AUTOSAR XML (schema 4-3-0)
standard types defined: boolean, uint16, uint8
package /Communication/Frames
  can frame DebugMsg1: frame-length=8
    pdu to frame mapping DebugMsg1: packing-byte-order=little-endian, pdu=DebugMsg1, start-position=0
package /Communication/NetworkManagement
  nm config NmConfig: can-nm-cluster-coupling=coupled-cluster=CAN00_CAN
    can nm cluster CAN00_CAN: communication-cluster=Comfort, nm-channel-id=0, nm-msg-cycle-time=2, nm-network-timeout=1, nm-repeat-message-time=0.4, nm-user-data-length=5, nm-wait-bus-sleep-time=0.75
      4 x can nm node, all with nm-car-wake-up-filter-enabled=false, nm-car-wake-up-rx-enabled=false, nm-msg-cycle-offset=0.01, nm-msg-reduced-time=0.05, nm-range-config={lower-can-id=1280, upper-can-id=1407}:
        Console: controller=Console/CT_CAN00, nm-if-ecu=Console_CAN, nm-node-id=-230, tx-nm-pdu=NM_Console
        DOOR_le: controller=DOOR_le/CT_CAN00, nm-if-ecu=DOOR_le_CAN, nm-node-id=-229, rx-nm-pdu=[NM_Console, NM_DOORright, NM_Gateway], tx-nm-pdu=NM_DOORleft
        DOOR_ri: controller=DOOR_ri/CT_CAN00, nm-if-ecu=DOOR_ri_CAN, nm-node-id=-228, rx-nm-pdu=[NM_Console, NM_DOORleft, NM_Gateway], tx-nm-pdu=NM_DOORright
        Gateway: controller=Gateway/CT_CAN00, nm-if-ecu=Gateway_CAN, nm-node-id=-227, rx-nm-pdu=[NM_Console, NM_DOORleft, NM_DOORright], tx-nm-pdu=NM_Gateway
    nm-if-ecus:
      4 x nm ecu, all with nm-node-id-enabled=true, nm-passive-mode-enabled=false, nm-user-data-enabled=true:
        Console_CAN: ecu-instance=Console
        DOOR_le_CAN: ecu-instance=DOOR_le
        DOOR_ri_CAN: ecu-instance=DOOR_ri
        Gateway_CAN: ecu-instance=Gateway
package /Communication/PDUs
  pdu Auth_PDU_1: length=8, transmission-mode-true-timing=cyclic-timing={time-offset=0, time-period=0.1}
    signal AuthPDU1_Signal1: start 0, 32 bit, little-endian, init-value=0, base-type=uint8
  pdu Auth_PDU_2: length=8, transmission-mode-true-timing=cyclic-timing={time-offset=0, time-period=0.1}
    signal AuthPDU2_Signal1: start 0, 32 bit, little-endian, init-value=0, base-type=uint8
  pdu DebugMsg1: length=8, minimum-delay=0, unused-bit-pattern=0
    signal DebugMsg1: start 0, 64 bit, opaque, init-value=8 x 0, base-type=uint8_8_iso_8859_1, compu {phys=raw for raw 0..1.84467440737096e+19}, transfer-property=PENDING, to Gateway
  18 x i signal i pdu group:
    Console_Rx: communication-direction=IN, i-signal-i-pdus=[Gateway_1, TP_Dashboard]
    Console_Tx: communication-direction=OUT, i-signal-i-pdus=[Console_1, Console_2, TP_Console]
    DOOR_le_Rx: communication-direction=IN, i-signal-i-pdus=Console_1
    DOOR_le_Tx: communication-direction=OUT, i-signal-i-pdus=DOOR_l
    DOOR_ri_Rx: communication-direction=IN, i-signal-i-pdus=Console_1
    DOOR_ri_Tx: communication-direction=OUT, i-signal-i-pdus=DOOR_r
    Dashboard_Rx: communication-direction=IN, i-signal-i-pdus=[Gateway_1, Gateway_2, TP_Console]
    Dashboard_Tx: communication-direction=OUT, i-signal-i-pdus=TP_Dashboard
    Gateway_Rx: communication-direction=IN, i-signal-i-pdus=DebugMsg1
    Gateway_Tx: communication-direction=OUT, i-signal-i-pdus=[Gateway_1, Gateway_2]
    PduGroup_203ad921c8f5452f95344f69f3b2c7c1_Tx: communication-direction=OUT
    PduGroup_2c8cbd7ae1c24b01b320fa2d7fbdce5a_Rx: communication-direction=IN
    PduGroup_42a827080d59494ea335cf739e6b9c29_Rx: communication-direction=IN
    PduGroup_4639c418dbec4715b125f02d3bcf57bf_Tx: communication-direction=OUT
    PduGroup_49c142dee3aa42039fa139536eb9d00c_Tx: communication-direction=OUT
    PduGroup_4a711ec297f94c7e811063aed12ba3a3_Rx: communication-direction=IN
    PduGroup_752b803f1d4a4f3696c5d022bdbd7b0a_Tx: communication-direction=OUT
    PduGroup_d31b664e874842edb94667f4a31f5902_Rx: communication-direction=IN
  pdu Multimedia_Contained1: length=20, contained-i-pdu-props={collection-semantics=LAST-IS-BEST, header-id-short-header=1, trigger=NEVER}, transmission-mode-true-timing={cyclic-timing=time-period=0.2, event-controlled-timing=number-of-repetitions=0}
    signal Multimedia_Contained1_Signal: start 0, 8 bit, little-endian, data-type-policy=OVERRIDE, base-type=uint16, to Dashboard
  pdu Multimedia_Contained2: length=20, contained-i-pdu-props={collection-semantics=LAST-IS-BEST, header-id-short-header=2, trigger=ALWAYS}, transmission-mode-condition{data-filter=data-filter-type=ALWAYS, i-signal-in-i-pdu=SignalPduMapping_683b95378b008a29}, transmission-mode-true-timing={cyclic-timing=time-period=0.1, event-controlled-timing=number-of-repetitions=0}
    signal Multimedia_Contained2_Signal: start 0, 8 bit, little-endian, data-type-policy=OVERRIDE, base-type=uint16, transfer-property=PENDING, to Dashboard
  pdu Multimedia_Contained3: length=30, contained-i-pdu-props={collection-semantics=LAST-IS-BEST, header-id-short-header=3, trigger=NEVER}, transmission-mode-true-timing=event-controlled-timing=number-of-repetitions=0
    signal Multimedia_Contained3_Signal: start 0, 64 bit, little-endian, data-type-policy=OVERRIDE, init-value=X64bit:23456789, base-type=uint16, to Dashboard
  pdu Multimedia_Contained4: length=30, contained-i-pdu-props={collection-semantics=LAST-IS-BEST, header-id-short-header=4, trigger=ALWAYS}, transmission-mode-true-timing=event-controlled-timing=number-of-repetitions=0
    signal Multimedia_Contained4_Signal: start 0, 32 bit, little-endian, data-type-policy=OVERRIDE, init-value=X32bit:012345, base-type=uint16, to Dashboard
package /Communication/Security
  secure communication props set SecurityConfigurarion
    secure communication authentication props AuthenticationProperties: auth-info-tx-length=24
    secure communication freshness props FreshnessProperties: freshness-value-length=8, freshness-value-tx-length=8
package /Communication/TransportProtocol
  can tp config CAN00_CAN: communication-cluster=Comfort
    can tp channel TPCH: channel-id=0, channel-mode=FULL-DUPLEX-MODE
package /DataTypes/ApplicationDataTypes
  app type Boolean: category=BOOLEAN
  app type String: category=STRING
package /DataTypes/BaseTypes
  base type uint8_6_iso_8859_1: category=FIXED_LENGTH, base-type-size=48, base-type-encoding=ISO-8859-1, mem-alignment=0
  base type uint8_8_iso_8859_1: category=FIXED_LENGTH, base-type-size=64, base-type-encoding=ISO-8859-1, mem-alignment=0
package /DataTypes/Units
  5 x unit:
    U_V: display-name=V
    U_degC: display-name=degC
    U_l: display-name=l
    U_mph: display-name=mph
    U_rpm: display-name=rpm
package /System
  system System
package /Topology/Clusters
  can cluster Comfort: baudrate=500000, protocol-name=CAN, can-fd-baudrate=4000000  # democomfort | CAN communication matrix for body electronics*******************************************************implemented: turn lights, warning lights, windows
    can physical channel CHNL: comm-connectors=[CN_CAN00_Console, CN_CAN00_DOOR_le, CN_CAN00_DOOR_ri, CN_CAN00_Dashboard, CN_CAN00_GW]
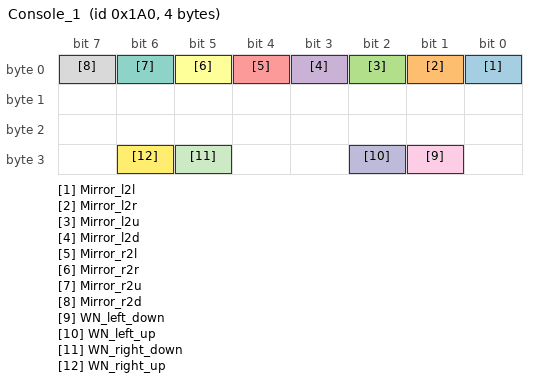
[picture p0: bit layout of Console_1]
      frame Console_1: id 0x1A0, from Console, to DOOR_le DOOR_ri, frame-length=4, can-addressing-mode=STANDARD, can-frame-tx-behavior=CAN-20
        pdu Console_1: length=4, minimum-delay=0.001, transmission-mode-false-timing=cyclic-timing={time-offset=0, time-period=0.02}, transmission-mode-true-timing=cyclic-timing={time-offset=0, time-period=0.02}, unused-bit-pattern=0
          signal Mirror_l2l: start 0, 1 bit, little-endian, init-value=0, base-type=boolean, compu {phys=raw for raw 0..1}, transfer-property=PENDING
          signal Mirror_l2r: start 1, 1 bit, little-endian, init-value=0, base-type=boolean, compu {phys=raw for raw 0..1}, transfer-property=PENDING
          signal Mirror_l2u: start 2, 1 bit, little-endian, init-value=0, base-type=boolean, compu {phys=raw for raw 0..1}, transfer-property=PENDING
          signal Mirror_l2d: start 3, 1 bit, little-endian, init-value=0, base-type=boolean, compu {phys=raw for raw 0..1}, transfer-property=PENDING
          signal Mirror_r2l: start 4, 1 bit, little-endian, init-value=0, base-type=boolean, compu {phys=raw for raw 0..1}, transfer-property=PENDING
          signal Mirror_r2r: start 5, 1 bit, little-endian, init-value=0, base-type=boolean, compu {phys=raw for raw 0..1}, transfer-property=PENDING
          signal Mirror_r2u: start 6, 1 bit, little-endian, init-value=0, base-type=boolean, compu {phys=raw for raw 0..1}, transfer-property=PENDING
          signal Mirror_r2d: start 7, 1 bit, little-endian, init-value=0, base-type=boolean, compu {phys=raw for raw 0..1}, transfer-property=PENDING
          signal WN_left_down: start 25, 1 bit, little-endian, init-value=0, base-type=boolean, compu {phys=raw for raw 0..1}, transfer-property=PENDING, to DOOR_le
          signal WN_left_up: start 26, 1 bit, little-endian, init-value=0, base-type=boolean, compu {phys=raw for raw 0..1}, transfer-property=PENDING, to DOOR_le
          signal WN_right_down: start 29, 1 bit, little-endian, init-value=0, base-type=boolean, compu {phys=raw for raw 0..1}, transfer-property=PENDING, to DOOR_ri
          signal WN_right_up: start 30, 1 bit, little-endian, init-value=0, base-type=boolean, compu {phys=raw for raw 0..1}, transfer-property=PENDING, to DOOR_ri
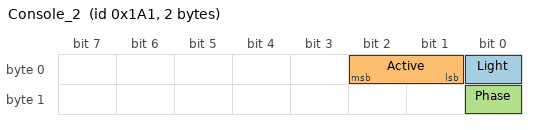
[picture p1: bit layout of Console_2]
      frame Console_2: id 0x1A1, from Console, frame-length=2, can-addressing-mode=STANDARD, can-frame-tx-behavior=CAN-20
        pdu Console_2: length=2, minimum-delay=0.001, transmission-mode-condition{data-filter={data-filter-type=MASKED-NEW-DIFFERS-X, mask=1, x=0}, i-signal-in-i-pdu=Light}, transmission-mode-false-timing=cyclic-timing=time-period=0.5, transmission-mode-true-timing=cyclic-timing=time-period=0.1, unused-bit-pattern=0
          signal Light: start 0, 1 bit, little-endian, init-value=0, base-type=boolean, compu {phys=raw for raw 0..1, 0=Light_Off, 1=Light_On}, transfer-property=PENDING
          signal Active: start 1, 2 bit, little-endian, init-value=0, base-type=uint8, compu {0=None, 1=Turn_right, 2=Turn_left, 3=Warning}, transfer-property=PENDING
          signal Phase: start 8, 1 bit, little-endian, init-value=0, base-type=boolean, compu {phys=raw for raw 0..1}, transfer-property=PENDING
      frame DOOR_l: id 0x1F0, from DOOR_le, frame-length=1, can-addressing-mode=STANDARD, can-frame-tx-behavior=CAN-20
        pdu DOOR_l: length=1, minimum-delay=0.001, transmission-mode-false-timing=cyclic-timing=time-period=0.03, transmission-mode-true-timing=cyclic-timing=time-period=0.03, unused-bit-pattern=0
          signal WN_Position: start 0, 8 bit, little-endian, init-value=0, base-type=uint8, compu {phys=raw*0.0625 for raw 0..255}, transfer-property=PENDING
      frame DOOR_r: id 0x1F1, from DOOR_ri, frame-length=1, can-addressing-mode=STANDARD, can-frame-tx-behavior=CAN-20
        pdu DOOR_r: length=1, minimum-delay=0.001, transmission-mode-false-timing=cyclic-timing=time-period=0.03, transmission-mode-true-timing=cyclic-timing=time-period=0.03, unused-bit-pattern=0
          signal WN_Position_Passenger: start 0, 8 bit, little-endian, init-value=0, base-type=uint8, compu {phys=raw*0.0625 for raw 0..255}, transfer-property=PENDING
      frame Diag_Request: id 0x700, frame-length=8, can-addressing-mode=STANDARD
        user defined pdu Diag_Request: length=8
      frame Diag_Response: id 0x600, frame-length=8, can-addressing-mode=STANDARD
        user defined pdu Diag_Response: length=8
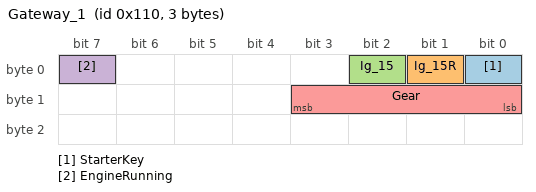
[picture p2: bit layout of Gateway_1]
      frame Gateway_1: id 0x110, from Gateway, to Console Dashboard, frame-length=3, can-addressing-mode=STANDARD, can-frame-tx-behavior=CAN-20
        pdu Gateway_1: length=3, minimum-delay=0.001, transmission-mode-false-timing=cyclic-timing=time-period=0.1, transmission-mode-true-timing=cyclic-timing=time-period=0.1, unused-bit-pattern=0
          signal StarterKey: start 0, 1 bit, little-endian, init-value=0, base-type=boolean, compu {phys=raw for raw 0..1}, transfer-property=PENDING, to Dashboard
          signal Ig_15R: start 1, 1 bit, little-endian, init-value=0, base-type=boolean, compu {phys=raw for raw 0..1}, transfer-property=PENDING, to Dashboard
          signal Ig_15: start 2, 1 bit, little-endian, init-value=0, base-type=boolean, compu {phys=raw for raw 0..1}, transfer-property=PENDING, to Console Dashboard
          signal EngineRunning: start 7, 1 bit, little-endian, init-value=0, base-type=boolean, compu {phys=raw for raw 0..1}, transfer-property=PENDING
          signal Gear: start 8, 4 bit, little-endian, init-value=0, base-type=uint8, compu {phys=raw for raw 0..15}, transfer-property=PENDING, to Dashboard
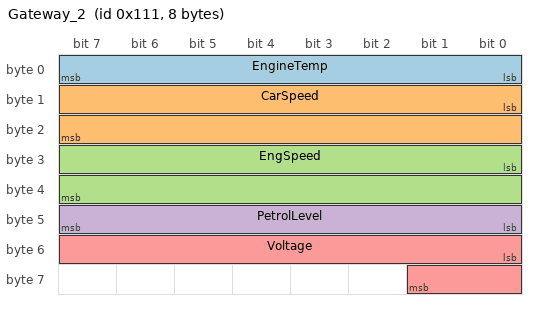
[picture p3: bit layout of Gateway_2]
      frame Gateway_2: id 0x111, from Gateway, to Dashboard, frame-length=8, can-addressing-mode=STANDARD, can-frame-tx-behavior=CAN-20
        pdu Gateway_2: length=8, minimum-delay=0.001, transmission-mode-false-timing={cyclic-timing=time-period=0.1, event-controlled-timing={number-of-repetitions=0, repetition-period=0}}, transmission-mode-true-timing={cyclic-timing=time-period=0.1, event-controlled-timing={number-of-repetitions=0, repetition-period=0}}, unused-bit-pattern=0
          transmission-mode-conditions:
            {data-filter={data-filter-type=MASKED-NEW-DIFFERS-MASKED-OLD, mask=255}, i-signal-in-i-pdu=EngineTemp}
            {data-filter={data-filter-type=MASKED-NEW-DIFFERS-MASKED-OLD, mask=255}, i-signal-in-i-pdu=PetrolLevel}
            {data-filter={data-filter-type=MASKED-NEW-DIFFERS-MASKED-OLD, mask=1023}, i-signal-in-i-pdu=Voltage}
            {data-filter={data-filter-type=MASKED-NEW-DIFFERS-MASKED-OLD, mask=65535}, i-signal-in-i-pdu=CarSpeed}
            {data-filter={data-filter-type=MASKED-NEW-DIFFERS-MASKED-OLD, mask=65535}, i-signal-in-i-pdu=EngSpeed}
          signal EngineTemp: start 0, 8 bit, little-endian, init-value=0, base-type=uint8, compu {phys=raw for raw 0..255; unit degC}, transfer-property=TRIGGERED, to Dashboard
          signal CarSpeed: start 8, 16 bit, little-endian, init-value=0, base-type=uint16, compu {phys=raw*0.5 for raw 0..65535; unit mph}, transfer-property=TRIGGERED, to Dashboard
          signal EngSpeed: start 24, 16 bit, little-endian, init-value=0, base-type=uint16, compu {phys=raw for raw 0..65535; unit rpm}, transfer-property=TRIGGERED, to Dashboard
          signal PetrolLevel: start 40, 8 bit, little-endian, init-value=0, base-type=uint8, compu {phys=raw for raw 0..255; unit l}, transfer-property=TRIGGERED, to Dashboard
          signal Voltage: start 48, 10 bit, little-endian, init-value=0, base-type=uint16, compu {phys=raw*0.1 for raw 0..1023; unit V}, transfer-property=TRIGGERED
      frame Mirror_Frame_1: id 0x7, from Dashboard, to Console, frame-length=16, can-addressing-mode=STANDARD, can-frame-tx-behavior=CAN-20
        pdu Mirror_Auth_PDU_1: length=16, transmission-mode-true-timing=cyclic-timing=time-period=0.1
          signal Mirror_Auth_PDU_1_NewSignal: start 0, 8 bit, little-endian, system signal Mirror_Auth_NewSignal_1, init-value=0, base-type=uint16, to Console
      frame Mirror_Frame_2: id 0x8, from Dashboard, to Console, frame-length=16, can-addressing-mode=STANDARD, can-frame-tx-behavior=CAN-20
        pdu Mirror_Auth_PDU_2: length=16, transmission-mode-true-timing=cyclic-timing=time-period=0.1
          signal Mirror_Auth_PDU_2_NewSignal: start 0, 8 bit, opaque, system signal Mirror_Auth_NewSignal_2, init-value=0, base-type=uint16, to Console
      frame NM_Console: id 0x41A, from Console, to DOOR_le DOOR_ri Dashboard Gateway, frame-length=4, can-addressing-mode=STANDARD, can-frame-tx-behavior=CAN-20
        nm pdu NM_Console: length=4, unused-bit-pattern=0
      frame NM_DOORleft: id 0x41B, from DOOR_le, to Console DOOR_ri Dashboard Gateway, frame-length=4, can-addressing-mode=STANDARD, can-frame-tx-behavior=CAN-20
        nm pdu NM_DOORleft: length=4, unused-bit-pattern=0
      frame NM_DOORright: id 0x41C, from DOOR_ri, to Console DOOR_le Dashboard Gateway, frame-length=4, can-addressing-mode=STANDARD, can-frame-tx-behavior=CAN-20
        nm pdu NM_DOORright: length=4, unused-bit-pattern=0
      frame NM_Gateway: id 0x41D, from Gateway, to Console DOOR_le DOOR_ri Dashboard, frame-length=4, can-addressing-mode=STANDARD, can-frame-tx-behavior=CAN-20
        nm pdu NM_Gateway: length=4, unused-bit-pattern=0
      frame ResetCounterSyncMessage: id 0x6, from Console, to Dashboard, frame-length=8, can-addressing-mode=STANDARD, can-frame-tx-behavior=CAN-20
        pdu ResetCounterSyncMessagePDU: length=3
          signal ResetCounterValueSignal: start 0, 24 bit, little-endian, data-type-policy=OVERRIDE
      frame ResetCounterSyncMessage_Sec: id 0x4, from Console, to Dashboard, frame-length=8, can-addressing-mode=STANDARD, can-frame-tx-behavior=CAN-FD
        secured i pdu ResetCounterSyncMessage_Sec: length=8, authentication-props=AuthenticationProperties, freshness-props=FreshnessProperties, payload=PT_ResetCounterSyncMessagePDU, secure-communication-props={auth-info-tx-length=24, data-id=22, freshness-value-id=2, freshness-value-tx-length=8, secondary-freshness-value-id=0}
        carries pdu ResetCounterValue: packing-byte-order=little-endian, start-position=64
        pdu ResetCounterValue: length=3
          signal ResetCounterValue: start 0, 24 bit, little-endian, data-type-policy=OVERRIDE
      frame Secured_Frame_1: id 0xC9, from Console, to Dashboard, frame-length=16, can-addressing-mode=STANDARD, can-frame-rx-behavior=CAN-FD, can-frame-tx-behavior=CAN-FD
        secured i pdu Secured_PDU_1: length=12, authentication-props=AuthenticationProperties, freshness-props=FreshnessProperties, payload=PT_AuthPDU1, secure-communication-props={auth-info-tx-length=24, data-id=33, freshness-value-tx-length=8}
      frame Secured_Frame_2: id 0xCA, from Console, to Dashboard, frame-length=16, can-addressing-mode=STANDARD, can-frame-rx-behavior=CAN-FD, can-frame-tx-behavior=CAN-FD
        secured i pdu Secured_PDU_2: length=12, authentication-props=AuthenticationProperties, freshness-props=FreshnessProperties, payload=PT_AuthPDU2, secure-communication-props={auth-info-tx-length=24, data-id=34, freshness-value-tx-length=8}
      frame TP_Console: id 0x604, from Console, to Dashboard, frame-length=6, can-addressing-mode=STANDARD, can-frame-tx-behavior=CAN-20
        pdu TP_Console: length=6, minimum-delay=0, unused-bit-pattern=0
          signal TP_Console: start 0, 48 bit, opaque, init-value=6 x 0, base-type=uint8_6_iso_8859_1, compu {phys=raw for raw 0..281474976710655}, transfer-property=PENDING, to Dashboard
      frame TP_Dashboard: id 0x605, from Dashboard, to Console, frame-length=6, can-addressing-mode=STANDARD, can-frame-tx-behavior=CAN-20
        pdu TP_Dashboard: length=6, minimum-delay=0, unused-bit-pattern=0
          signal TP_Dashboard: start 0, 48 bit, opaque, init-value=6 x 0, base-type=uint8_6_iso_8859_1, compu {phys=raw for raw 0..281474976710655}, transfer-property=PENDING, to Console
      frame TripCounterSyncMessage: id 0x5, from Console, to Dashboard, frame-length=8, can-addressing-mode=STANDARD, can-frame-tx-behavior=CAN-FD
        pdu TripCounterSyncMessagePDU: length=3
          signal TripCounterValueSignal: start 0, 24 bit, little-endian, data-type-policy=OVERRIDE
      frame TripCounterSyncMessage_Sec: id 0x3, from Console, to Dashboard, frame-length=8, can-addressing-mode=STANDARD, can-frame-tx-behavior=CAN-FD
        secured i pdu TripCounterSyncMessage_Sec: length=8, authentication-props=AuthenticationProperties, freshness-props=FreshnessProperties, payload=PT_TripCounterSyncMessagePDU, secure-communication-props={auth-info-tx-length=24, data-id=11, freshness-value-id=1, freshness-value-tx-length=8, secondary-freshness-value-id=0}
        carries pdu TripCounterValue: packing-byte-order=little-endian, start-position=64
        pdu TripCounterValue: length=3
          signal TripCounterValue: start 0, 24 bit, little-endian, data-type-policy=OVERRIDE
      frame Mulitmedia_Frame: id 0xC8, from Console, to Dashboard, frame-length=64, can-addressing-mode=EXTENDED
        container i pdu Multimedia: length=64, contained-pdu-triggering=[PT_Multimedia_Contained1, PT_Multimedia_Contained2, PT_Multimedia_Contained3, PT_Multimedia_Contained4], container-timeout=0.2, container-trigger=DEFAULT-TRIGGER, header-type=SHORT-HEADER, rx-accept-contained-i-pdu=ACCEPT-CONFIGURED, threshold-size=60
      frame WiperSystem: id 0x1, from Dashboard, frame-length=8, can-addressing-mode=STANDARD, can-frame-tx-behavior=CAN-20
        pdu WiperPosition: length=4, minimum-delay=0.001, transmission-mode-true-timing=cyclic-timing=time-period=0.03
          signal WiperPosition: start 0, 4 bit, little-endian, system signal WiperPosition_3b8b5377bfae9a8b, data-type-policy=OVERRIDE, base-type=uint8
      pdu triggering PT_AuthPDU1: pdu=Auth_PDU_1, from Console, to Dashboard
      pdu triggering PT_AuthPDU2: pdu=Auth_PDU_2, from Console, to Dashboard
      pdu triggering PT_Multimedia_Contained{1..4}: pdu=Multimedia_Contained{1..4}, from Console, to Dashboard
package /Topology/HardwareComponents
  5 x ecu instance, all with sleep-mode-supported=false, wake-up-over-bus-supported=false:
    Console: associated-com-i-pdu-group=[Console_Rx, Console_Tx, PduGroup_203ad921c8f5452f95344f69f3b2c7c1_Tx, PduGroup_4639c418dbec4715b125f02d3bcf57bf_Tx, PduGroup_49c142dee3aa42039fa139536eb9d00c_Tx, PduGroup_752b803f1d4a4f3696c5d022bdbd7b0a_Tx]
      can communication controller CT_CAN00: can-controller-attributes=can-controller-configuration-requirements={max-number-of-time-quanta-per-bit=20, max-sample-point=81.25, min-number-of-time-quanta-per-bit=15, min-sample-point=80}
      can communication connector CN_CAN00_Console: comm-controller=Console/CT_CAN00
    DOOR_le: associated-com-i-pdu-group=[DOOR_le_Rx, DOOR_le_Tx]
      can communication controller CT_CAN00: can-controller-attributes=can-controller-configuration-requirements={max-number-of-time-quanta-per-bit=20, max-sample-point=81.25, min-number-of-time-quanta-per-bit=15, min-sample-point=80}
      can communication connector CN_CAN00_DOOR_le: comm-controller=DOOR_le/CT_CAN00
    DOOR_ri: associated-com-i-pdu-group=[DOOR_ri_Rx, DOOR_ri_Tx]
      can communication controller CT_CAN00: can-controller-attributes=can-controller-configuration-requirements={max-number-of-time-quanta-per-bit=20, max-sample-point=81.25, min-number-of-time-quanta-per-bit=15, min-sample-point=80}
      can communication connector CN_CAN00_DOOR_ri: comm-controller=DOOR_ri/CT_CAN00
    Dashboard: associated-com-i-pdu-group=[Dashboard_Rx, Dashboard_Tx, PduGroup_2c8cbd7ae1c24b01b320fa2d7fbdce5a_Rx, PduGroup_42a827080d59494ea335cf739e6b9c29_Rx, PduGroup_4a711ec297f94c7e811063aed12ba3a3_Rx, PduGroup_d31b664e874842edb94667f4a31f5902_Rx, PduGroup_cbe4f70a071b4b85a433ff89724d6ba2_Tx]
      can communication controller CT_CAN00: can-controller-attributes=can-controller-configuration-requirements={max-number-of-time-quanta-per-bit=20, max-sample-point=81.25, min-number-of-time-quanta-per-bit=15, min-sample-point=80}
      can communication connector CN_CAN00_Dashboard: comm-controller=Dashboard/CT_CAN00
    Gateway: associated-com-i-pdu-group=[Gateway_Rx, Gateway_Tx]
      can communication controller CT_CAN00: can-controller-attributes=can-controller-configuration-requirements={max-number-of-time-quanta-per-bit=20, max-sample-point=81.25, min-number-of-time-quanta-per-bit=15, min-sample-point=80}
      can communication connector CN_CAN00_GW: comm-controller=Gateway/CT_CAN00
package /VectorAutosarExplorerGeneratedObjects/PDU_GROUP
  i signal i pdu group PduGroup_cbe4f70a071b4b85a433ff89724d6ba2_Tx: communication-direction=OUT
